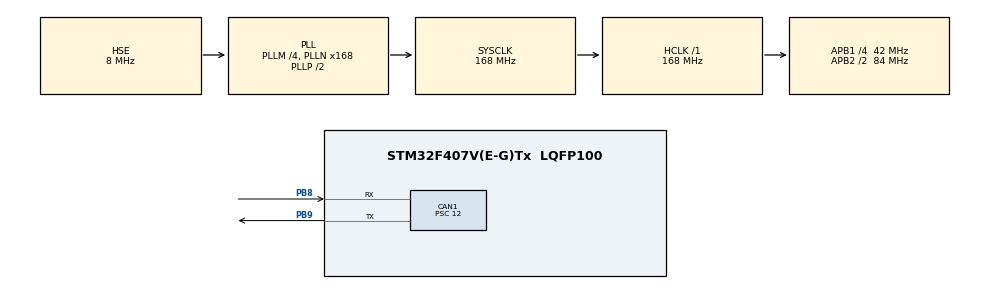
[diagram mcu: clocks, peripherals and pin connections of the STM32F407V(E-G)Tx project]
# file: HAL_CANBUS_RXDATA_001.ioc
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CAN1.BS1=CAN_BS1_2TQ
CAN1.BS2=CAN_BS2_4TQ
CAN1.CalculateBaudRate=500000
CAN1.CalculateTimeBit=2000
CAN1.CalculateTimeQuantum=285.7142857142857
CAN1.Prescaler=12
Mcu.Family=STM32F4
Mcu.Name=STM32F407V(E-G)Tx
Mcu.Package=LQFP100
NVIC.PriorityGroup=NVIC_PRIORITYGROUP_4
PA13.Mode=Serial_Wire
PA13.Signal=SYS_JTMS-SWDIO
PA14.Mode=Serial_Wire
PA14.Signal=SYS_JTCK-SWCLK
PB8.Mode=CAN_Activate
PB8.Signal=CAN1_RX
PB9.Mode=CAN_Activate
PB9.Signal=CAN1_TX
PH0-OSC_IN.Mode=HSE-External-Oscillator
PH0-OSC_IN.Signal=RCC_OSC_IN
PH1-OSC_OUT.Mode=HSE-External-Oscillator
PH1-OSC_OUT.Signal=RCC_OSC_OUT
ProjectManager.HeapSize=0x200
ProjectManager.StackSize=0x400
ProjectManager.TargetToolchain=STM32CubeIDE
RCC.48MHZClocksFreq_Value=84000000
RCC.AHBFreq_Value=168000000
RCC.APB1CLKDivider=RCC_HCLK_DIV4
RCC.APB1Freq_Value=42000000
RCC.APB1TimFreq_Value=84000000
RCC.APB2CLKDivider=RCC_HCLK_DIV2
RCC.APB2Freq_Value=84000000
RCC.APB2TimFreq_Value=168000000
RCC.CortexFreq_Value=168000000
RCC.HCLKFreq_Value=168000000
RCC.HSE_VALUE=8000000
RCC.HSI_VALUE=16000000
RCC.LSE_VALUE=32768
RCC.PLLM=4
RCC.PLLN=168
RCC.PLLSourceVirtual=RCC_PLLSOURCE_HSE
RCC.SYSCLKFreq_VALUE=168000000
RCC.SYSCLKSource=RCC_SYSCLKSOURCE_PLLCLK
RCC.VCOOutputFreq_Value=336000000
board=custom

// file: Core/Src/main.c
/* USER CODE BEGIN Header */
/**
  ******************************************************************************
  * @file           : main.c
  * @brief          : Main program body
  ******************************************************************************
  * @attention
  *
  * Copyright (c) 2024 STMicroelectronics.
  * All rights reserved.
  *
  * This software is licensed under terms that can be found in the LICENSE file
  * in the root directory of this software component.
  * If no LICENSE file comes with this software, it is provided AS-IS.
  *
  ******************************************************************************
  */
/* USER CODE END Header */
#include "main.h"

/* USER CODE BEGIN Includes */

CAN_RxHeaderTypeDef CanRxHandle;
uint32_t CanRxFifo = CAN_RX_FIFO0;
uint8_t CanRxData[8];
uint32_t TransmitterData[8];

/* USER CODE END Includes */

CAN_HandleTypeDef hcan1;

void SystemClock_Config(void);
static void MX_GPIO_Init(void);
static void MX_CAN1_Init(void);

int main(void)
{

  /* MCU Configuration--------------------------------------------------------*/

  /* Reset of all peripherals, Initializes the Flash interface and the Systick. */
  HAL_Init();

  /* Configure the system clock */
  SystemClock_Config();

  /* Initialize all configured peripherals */
  MX_GPIO_Init();
  MX_CAN1_Init();
  /* USER CODE BEGIN 2 */

//  CanRxHandle.DLC = 8;
//  CanRxHandle.IDE = CAN_ID_STD;
//  CanRxHandle.StdId = 0x35;

  HAL_CAN_Start(&hcan1);

  /* USER CODE END 2 */

  /* Infinite loop */
  while (1)
  {

    /* USER CODE BEGIN 3 */
	  HAL_CAN_GetRxMessage(&hcan1,CanRxFifo, &CanRxHandle, CanRxData);
	  TransmitterData[0] = CanRxHandle.StdId;
	  TransmitterData[1] = CanRxHandle.ExtId;
	  TransmitterData[2] = CanRxHandle.IDE;
	  TransmitterData[3] = CanRxHandle.RTR;
	  TransmitterData[4] = CanRxHandle.DLC;

  }
  /* USER CODE END 3 */
}

void SystemClock_Config(void)
{
  RCC_OscInitTypeDef RCC_OscInitStruct = {0};
  RCC_ClkInitTypeDef RCC_ClkInitStruct = {0};

  /** Configure the main internal regulator output voltage
  */
  __HAL_RCC_PWR_CLK_ENABLE();
  __HAL_PWR_VOLTAGESCALING_CONFIG(PWR_REGULATOR_VOLTAGE_SCALE1);

  /** Initializes the RCC Oscillators according to the specified parameters
  * in the RCC_OscInitTypeDef structure.
  */
  RCC_OscInitStruct.OscillatorType = RCC_OSCILLATORTYPE_HSE;
  RCC_OscInitStruct.HSEState = RCC_HSE_ON;
  RCC_OscInitStruct.PLL.PLLState = RCC_PLL_ON;
  RCC_OscInitStruct.PLL.PLLSource = RCC_PLLSOURCE_HSE;
  RCC_OscInitStruct.PLL.PLLM = 4;
  RCC_OscInitStruct.PLL.PLLN = 168;
  RCC_OscInitStruct.PLL.PLLP = RCC_PLLP_DIV2;
  RCC_OscInitStruct.PLL.PLLQ = 4;
  if (HAL_RCC_OscConfig(&RCC_OscInitStruct) != HAL_OK)
  {
    Error_Handler();
  }

  /** Initializes the CPU, AHB and APB buses clocks
  */
  RCC_ClkInitStruct.ClockType = RCC_CLOCKTYPE_HCLK|RCC_CLOCKTYPE_SYSCLK
                              |RCC_CLOCKTYPE_PCLK1|RCC_CLOCKTYPE_PCLK2;
  RCC_ClkInitStruct.SYSCLKSource = RCC_SYSCLKSOURCE_PLLCLK;
  RCC_ClkInitStruct.AHBCLKDivider = RCC_SYSCLK_DIV1;
  RCC_ClkInitStruct.APB1CLKDivider = RCC_HCLK_DIV4;
  RCC_ClkInitStruct.APB2CLKDivider = RCC_HCLK_DIV2;

  if (HAL_RCC_ClockConfig(&RCC_ClkInitStruct, FLASH_LATENCY_5) != HAL_OK)
  {
    Error_Handler();
  }
}

static void MX_CAN1_Init(void)
{

  hcan1.Instance = CAN1;
  hcan1.Init.Prescaler = 12;
  hcan1.Init.Mode = CAN_MODE_NORMAL;
  hcan1.Init.SyncJumpWidth = CAN_SJW_1TQ;
  hcan1.Init.TimeSeg1 = CAN_BS1_2TQ;
  hcan1.Init.TimeSeg2 = CAN_BS2_4TQ;
  hcan1.Init.TimeTriggeredMode = DISABLE;
  hcan1.Init.AutoBusOff = DISABLE;
  hcan1.Init.AutoWakeUp = DISABLE;
  hcan1.Init.AutoRetransmission = DISABLE;
  hcan1.Init.ReceiveFifoLocked = DISABLE;
  hcan1.Init.TransmitFifoPriority = DISABLE;
  if (HAL_CAN_Init(&hcan1) != HAL_OK)
  {
    Error_Handler();
  }
  /* USER CODE BEGIN CAN1_Init 2 */

  // Can Haberleşmesinde Filtre Uygulaması.
  CAN_FilterTypeDef CanFilterHandle;

  CanFilterHandle.FilterActivation = CAN_FILTER_ENABLE;
  CanFilterHandle.FilterScale = CAN_FILTERSCALE_32BIT;
  CanFilterHandle.FilterMode = CAN_FILTERMODE_IDMASK;
  CanFilterHandle.FilterFIFOAssignment = CAN_FILTER_FIFO0;
  CanFilterHandle.SlaveStartFilterBank = 20;
  CanFilterHandle.FilterBank = 18;

  /* USER CODE END CAN1_Init 2 */

}

static void MX_GPIO_Init(void)
{

  /* GPIO Ports Clock Enable */
  __HAL_RCC_GPIOH_CLK_ENABLE();
  __HAL_RCC_GPIOA_CLK_ENABLE();
  __HAL_RCC_GPIOB_CLK_ENABLE();

}

void Error_Handler(void)
{
  __disable_irq();
  while (1)
  {
  }
}
